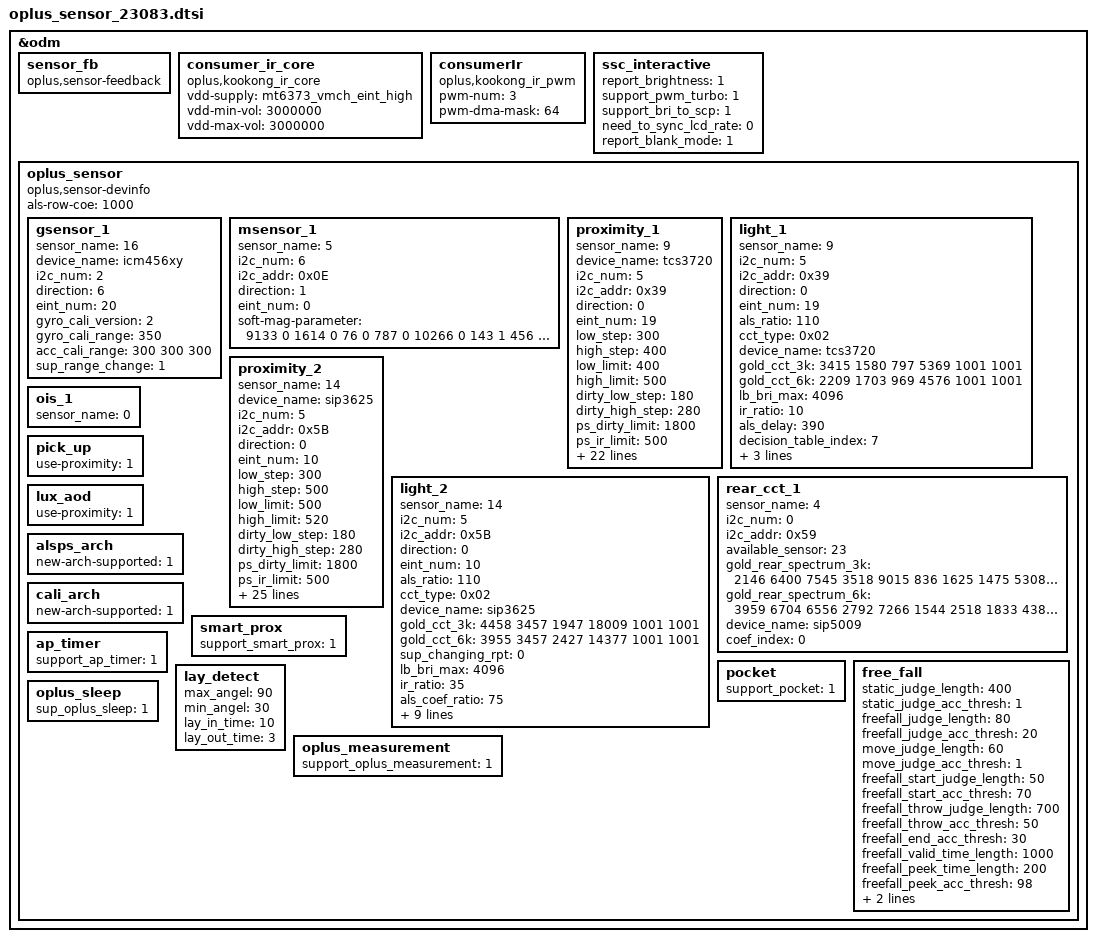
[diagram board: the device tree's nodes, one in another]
&odm {
	sensor_fb: sensor_fb {
		compatible = "oplus,sensor-feedback";
	};
	consumer_ir_core: consumer_ir_core {
		compatible = "oplus,kookong_ir_core";
		status = "okay";
		vdd-supply = <&mt6373_vmch_eint_high>;
		vdd-min-vol = <3000000>;
		vdd-max-vol = <3000000>;
	};
	consumerIr: consumerIr {
		compatible = "oplus,kookong_ir_pwm";
		status = "okay";
		pwm-num = <3>;
		pwm-dma-mask = <64>;
	};
	ssc_interactive: ssc_interactive {
		report_brightness = <1>;
		support_pwm_turbo = <1>;
		support_bri_to_scp = <1>;
		need_to_sync_lcd_rate = <0>;
		report_blank_mode = <1>;
	};
	oplus_sensor:oplus_sensor {
		compatible = "oplus,sensor-devinfo";
		als-row-coe = <1000>;
		/* sensor start */
		/*
		enum {
			LIS3DH,
			LSM6DS3,
			BMI160,
			LIS2HH12,
			LSM6DSM,
			BMI2XY,
			LSM6DSO,
			BMA4XY,
			SC7A20,
			ICM4X6XX,
			ICM456XY,
		};
		*/
		gsensor_1: gsensor_1 {
			status = "okay";
			sensor_name = <16>;// icm456xy
			device_name = "icm456xy";
			i2c_num = <2>;
			direction = <6>;
			eint_num = <20>;
			gyro_cali_version= <2>;
			gyro_cali_range =<350>;
			acc_cali_range= <300 300 300>;
			sup_range_change = <1>;
		};
		/*
		enum {
			AKM09911,
			MMC3530,
			MMC5603,
			MXG4300,
			AKM09918,
			AKM09919,
		};
		*/
		msensor_1: msensor_1 {
			status = "okay";
			sensor_name = <5>;//AKM09919
			i2c_num = <6>;
			i2c_addr = <0x0E>;
			direction = <1>;
			eint_num = <0>;
			soft-mag-parameter = <9133 0 1614 0 76 0 787 0 10266 0 143 1 456 0 489 1 10302 0>;
		};
		/*
		enum {
			TMD2725,
			APSD9922,
			STK3335,
			STK3331,
			STK2232,
			TCS3701,
			STK32600,
			STK33502,
			MN78911,
			TCS3720,
		};
		*/
		proximity_1: proximity_1 {
			status = "okay";
			sensor_name = <9>;//TCS3720
			device_name = "tcs3720";
			i2c_num = <5>;
			i2c_addr = <0x39>;
			direction = <0>;
			eint_num = <19>;
			low_step = <300>;
			high_step = <400>;
			low_limit = <400>;
			high_limit = <500>;
			dirty_low_step = <180>;
			dirty_high_step = <280>;
			ps_dirty_limit = <1800>;
			ps_ir_limit = <500>;
			ps_adjust_min = <0>;
			ps_adjust_max = <850>;
			sampling_count = <5>;
			step_max = <400>;
			step_min = <100>;
			step_div = <2000>;
			anti_shake_delta = <120>;
			dynamic_cali_max = <3000>;
			raw2offset_radio = <1000>;
			offset_max = <16000>;
			offset_range_min = <0>;
			offset_range_max = <65534>;
			force_cali_limit = <0>;
			cali_jitter_limit = <85>;
			cal_offset_margin = <3001>;
			sensor-reg = <0xB1 0x0C 0x82 0xE2>;
			60hz_psd_us = <14200>;
			90hz_psd_us = <10600>;
			120hz_psd_us = <7900>;
			ps_check_num = <3>;
			ps_mid_filter = <0>;
			need_to_sync_lcd_rate = <0>;
		};
		light_1: light_1 {
			status = "okay";
			sensor_name = <9>;//TCS3720
			i2c_num = <5>;
			i2c_addr = <0x39>;
			direction = <0>;
			eint_num = <19>;
			als_ratio = <110>;
			cct_type = <0x02>; //0x01 CCT_NORMAL 0x02 CCT_WISE
			device_name = "tcs3720";
			gold_cct_3k = <3415 1580 797 5369 1001 1001>;
			gold_cct_6k = <2209 1703 969 4576 1001 1001>;
			lb_bri_max = <4096>;
			ir_ratio = <10>; // *1000
			als_delay = <390>;
			decision_table_index = <7>;
			available_sensor = <14>;
			gold_cct_factor = <941 946 924 966 1001 1001>;
			high_pwm_cct = <1>;
		};
		proximity_2: proximity_2 {
			status = "okay";
			sensor_name = <14>; // SIP3625
			device_name = "sip3625";
			i2c_num = <5>;
			i2c_addr = <0x5B>;
			direction = <0>;
			eint_num = <10>;
			low_step = <300>;
			high_step = <500>;
			low_limit = <500>;
			high_limit = <520>;
			dirty_low_step = <180>;
			dirty_high_step = <280>;
			ps_dirty_limit = <1800>;
			ps_ir_limit = <500>;
			ps_adjust_min = <300>;
			ps_adjust_max = <800>;
			sampling_count = <5>;
			step_max = <400>;
			step_min = <100>;
			step_div = <2000>;
			anti_shake_delta = <120>;
			dynamic_cali_max = <1400>;
			raw2offset_radio = <5000>;
			offset_max = <15000>;
			offset_range_min = <0>;
			offset_range_max = <65534>;
			force_cali_limit = <5116>;
			cali_jitter_limit = <70>;
			cal_offset_margin = <3000>;
			60hz_psd_us = <13500>;
			90hz_psd_us = <7944>;
			120hz_psd_us = <5166>;
			ps_check_num = <3>;
			ps_mid_filter = <0>;
			need_to_sync_lcd_rate = <0>;
			ps_power_config = <1>;
			dmc_flt_thr = <100>;
			multi_oft_level = <3>;
			multi_oft_coef = <130 26 1>;
		};
		light_2: light_2 {
			status = "okay";
			sensor_name = <14>;//SIP3625
			i2c_num = <5>;
			i2c_addr = <0x5B>;
			direction = <0>;
			eint_num = <10>;
			als_ratio = <110>;
			cct_type = <0x02>; //0x01 CCT_NORMAL 0x02 CCT_WISE
			device_name = "sip3625";
			gold_cct_3k = <4458 3457 1947 18009 1001 1001>;
			gold_cct_6k = <3955 3457 2427 14377 1001 1001>;
			sup_changing_rpt = <0>;
			lb_bri_max = <4096>;
			ir_ratio = <35>; // *100
			als_coef_ratio = <75>; // *100
			als_delay = <390>;
			decision_table_index = <1>;
			available_sensor = <14>;
			gold_cct_factor = <941 946 924 966 1001 1001>;
			high_pwm_cct = <1>;
			als_timer_ms = <100>;
			als_buffer_length = <2>;
			need_gain_cali = <0>;
			atime = <25000>;
		};
		rear_cct_1: rear_cct_1 {
			status = "okay";
			sensor_name = <4>; // sip5009
			i2c_num = <0>;
			i2c_addr = <0x59>;
			available_sensor = <23>; // bit 0: rear als, bit 1: rear cct, bit 2: rear flicker, bit 3: rear proximity
			gold_rear_spectrum_3k = <2146 6400 7545 3518 9015 836 1625 1475 5308 1248 5430 6258 2539>; // Z Y X NIR VIS F2 F3 F4 F6 F1 F7 F8 F5 F
			gold_rear_spectrum_6k = <3959 6704 6556 2792 7266 1544 2518 1833 4385 2239 3868 3404 2488>;
			device_name = "sip5009";
			coef_index = <0>;
		};
		ois_1: ois_1 {
			status = "okay";
			sensor_name = <0>;
		};
		pick_up: pick_up {
			status = "okay";
			use-proximity = <1>;
		};
		lux_aod: lux_aod {
			status = "okay";
			use-proximity = <1>;
		};
		alsps_arch: alsps_arch {
			status = "okay";
			new-arch-supported = <1>;
		};
		cali_arch: cali_arch {
			status = "okay";
			new-arch-supported = <1>;
		};
		smart_prox: smart_prox {
			status = "okay";
			support_smart_prox = <1>;
		};
		ap_timer: ap_timer {
			status = "okay";
			support_ap_timer = <1>;
		};
		pocket: pocket {
			status = "okay";
			support_pocket = <1>;
		};
		free_fall: free_fall{
			status = "okay";
			static_judge_length = <400>;
			static_judge_acc_thresh = <1>;
			freefall_judge_length = <80>;
			freefall_judge_acc_thresh = <20>;
			move_judge_length = <60>;
			move_judge_acc_thresh = <1>;
			freefall_start_judge_length  = <50>;
			freefall_start_acc_thresh = <70>;
			freefall_throw_judge_length = <700>;
			freefall_throw_acc_thresh = <50>;
			freefall_end_acc_thresh = <30>;
			freefall_valid_time_length = <1000>;
			freefall_peek_time_length = <200>;
			freefall_peek_acc_thresh = <98>;
			freefall_material_thresh = <900>;
			valid_peek_interval_thresh = <10000>;
		};
		lay_detect: lay_detect{
			status = "okay";
			max_angel = <90>;
			min_angel = <30>;
			lay_in_time = <10>;
			lay_out_time = <3>;
		};
		oplus_measurement: oplus_measurement{
			status = "okay";
			support_oplus_measurement = <1>;
		};
		oplus_sleep: oplus_sleep{
			status = "okay";
			sup_oplus_sleep = <1>;
		};
	};
/* sensor end */
};
